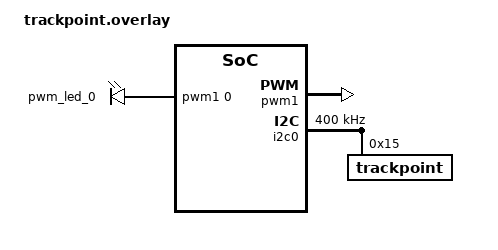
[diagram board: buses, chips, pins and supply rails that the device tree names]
/*
*
* Copyright (c) 2025 ZitaoTech
* SPDX-License-Identifier: MIT
*
*/

/ {
    chosen {
        zmk,custom_led = &custom_led;
    };
    custom_led: pwmledto{
        compatible = "pwm-leds";
        pwm_led_0 {
            pwms = <&pwm1 0 PWM_USEC(20) PWM_POLARITY_NORMAL>;
        };
    };

};

&pwm1 {
    status = "okay";
    pinctrl-0 = <&pwm1_default>;
    pinctrl-1 = <&pwm1_sleep>;
    pinctrl-names = "default", "sleep";
};

&i2c0 {
    status = "okay";
    compatible = "nordic,nrf-twim";
    clock-frequency = <I2C_BITRATE_FAST>; 
    pinctrl-0 = <&i2c0_default>;
    pinctrl-1 = <&i2c0_sleep>;
    pinctrl-names = "default", "sleep";

    trackpoint:trackpoint@15 {
        compatible = "zmk,trackpoint";
        reg = <0x15>;
        status = "okay";
    };
};

/ {
    split_inputs {
        #address-cells = <1>;
        #size-cells = <0>;

        /* BB Trackball */
        trackpoint_split: trackpoint_split@0 {
            compatible = "zmk,input-split";
            reg = <0>;
        };

    };

    /* Listeners */
    trackpoint_listener: trackpoint_listener {
        compatible = "zmk,input-listener";
        status = "disabled";
        device = <&trackpoint_split>;
    };

};


&trackpoint_split {
    device = <&trackpoint>;
};

/* 引脚定义在 config/sofle_dongle_right.overlay（属于板子，不属于模块） */

